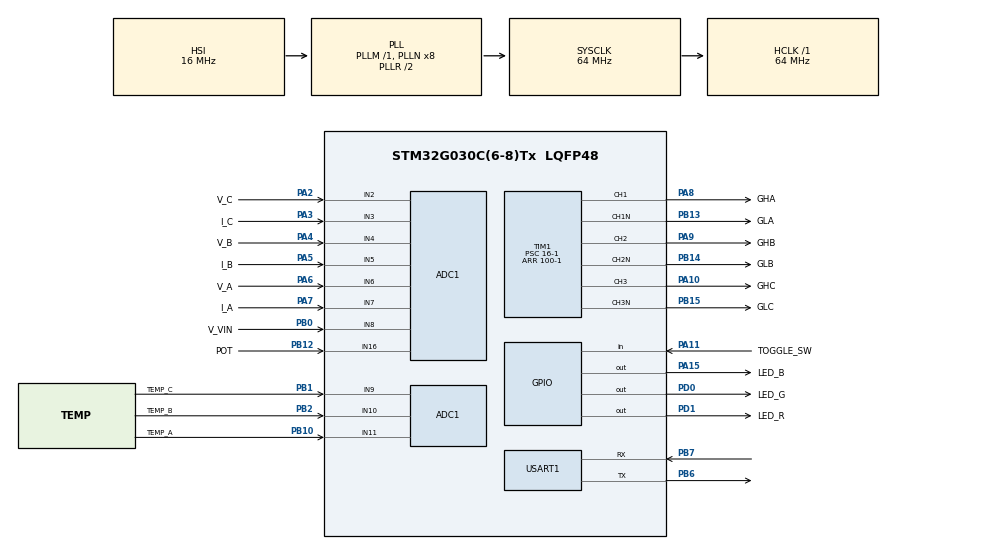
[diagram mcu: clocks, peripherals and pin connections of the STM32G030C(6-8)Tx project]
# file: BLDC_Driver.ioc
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ADC1.Channel-0\#ChannelRegularConversion=ADC_CHANNEL_2
ADC1.ContinuousConvMode=DISABLE
ADC1.DMAContinuousRequests=ENABLE
ADC1.EOCSelection=ADC_EOC_SINGLE_CONV
ADC1.ExternalTrigConv=ADC_EXTERNALTRIG_T1_TRGO2
ADC1.NbrOfConversion=1
ADC1.NbrOfConversionFlag=1
ADC1.Rank-0\#ChannelRegularConversion=1
ADC1.SamplingTime-0\#ChannelRegularConversion=__NULL
ADC1.SamplingTimeCommon1=ADC_SAMPLETIME_1CYCLE_5
ADC1.SelectedChannel=ADC_CHANNEL_2|ADC_CHANNEL_3|ADC_CHANNEL_4|ADC_CHANNEL_5|ADC_CHANNEL_6|ADC_CHANNEL_7|ADC_CHANNEL_8|ADC_CHANNEL_9|ADC_CHANNEL_10|ADC_CHANNEL_11|ADC_CHANNEL_16
ADC1.Sequencer=NOT_FULLY_CONFIGURABLE
ADC1.master=1
Dma.ADC1.0.Direction=DMA_PERIPH_TO_MEMORY
Dma.ADC1.0.EventEnable=DISABLE
Dma.ADC1.0.Instance=DMA1_Channel1
Dma.ADC1.0.MemDataAlignment=DMA_MDATAALIGN_HALFWORD
Dma.ADC1.0.MemInc=DMA_MINC_ENABLE
Dma.ADC1.0.Mode=DMA_CIRCULAR
Dma.ADC1.0.PeriphDataAlignment=DMA_PDATAALIGN_HALFWORD
Dma.ADC1.0.PeriphInc=DMA_PINC_DISABLE
Dma.ADC1.0.Polarity=HAL_DMAMUX_REQ_GEN_RISING
Dma.ADC1.0.Priority=DMA_PRIORITY_LOW
Dma.ADC1.0.RequestNumber=1
Dma.ADC1.0.SignalID=NONE
Dma.ADC1.0.SyncEnable=DISABLE
Dma.ADC1.0.SyncPolarity=HAL_DMAMUX_SYNC_NO_EVENT
Dma.ADC1.0.SyncRequestNumber=1
Dma.ADC1.0.SyncSignalID=NONE
Dma.Request0=ADC1
Dma.Request1=USART1_TX
Dma.USART1_TX.1.Direction=DMA_MEMORY_TO_PERIPH
Dma.USART1_TX.1.EventEnable=DISABLE
Dma.USART1_TX.1.Instance=DMA1_Channel2
Dma.USART1_TX.1.MemDataAlignment=DMA_MDATAALIGN_BYTE
Dma.USART1_TX.1.MemInc=DMA_MINC_ENABLE
Dma.USART1_TX.1.Mode=DMA_NORMAL
Dma.USART1_TX.1.PeriphDataAlignment=DMA_PDATAALIGN_BYTE
Dma.USART1_TX.1.PeriphInc=DMA_PINC_DISABLE
Dma.USART1_TX.1.Polarity=HAL_DMAMUX_REQ_GEN_RISING
Dma.USART1_TX.1.Priority=DMA_PRIORITY_LOW
Dma.USART1_TX.1.RequestNumber=1
Dma.USART1_TX.1.SignalID=NONE
Dma.USART1_TX.1.SyncEnable=DISABLE
Dma.USART1_TX.1.SyncPolarity=HAL_DMAMUX_SYNC_NO_EVENT
Dma.USART1_TX.1.SyncRequestNumber=1
Dma.USART1_TX.1.SyncSignalID=NONE
Mcu.Family=STM32G0
Mcu.Name=STM32G030C(6-8)Tx
Mcu.Package=LQFP48
NVIC.ADC1_IRQn=true\:0\:0\:false\:false\:true\:true\:true\:true
NVIC.DMA1_Channel1_IRQn=true\:0\:0\:false\:false\:true\:false\:true\:true
NVIC.DMA1_Channel2_3_IRQn=true\:0\:0\:false\:false\:true\:false\:true\:true
NVIC.TIM14_IRQn=true\:1\:0\:true\:false\:true\:true\:true\:true
NVIC.TIM16_IRQn=true\:0\:0\:true\:false\:true\:true\:true\:true
NVIC.TIM17_IRQn=true\:0\:0\:false\:false\:true\:true\:true\:true
NVIC.TIM1_BRK_UP_TRG_COM_IRQn=true\:0\:0\:false\:false\:true\:true\:true\:true
NVIC.TIM1_CC_IRQn=true\:0\:0\:false\:false\:true\:true\:true\:true
NVIC.USART1_IRQn=true\:0\:0\:false\:false\:true\:true\:true\:true
PA10.GPIO_Label=GHC
PA10.Signal=S_TIM1_CH3
PA11\ [PA9].GPIO_Label=TOGGLE_SW
PA11\ [PA9].GPIO_PuPd=GPIO_PULLDOWN
PA11\ [PA9].Signal=GPIO_Input
PA13.Mode=Serial_Wire
PA13.Signal=SYS_SWDIO
PA14-BOOT0.Mode=Serial_Wire
PA14-BOOT0.Signal=SYS_SWCLK
PA15.GPIO_Label=LED_B
PA15.GPIO_PuPd=GPIO_PULLDOWN
PA15.Signal=GPIO_Output
PA2.GPIO_Label=V_C
PA2.Mode=IN2
PA2.Signal=ADC1_IN2
PA3.GPIO_Label=I_C
PA3.Mode=IN3
PA3.Signal=ADC1_IN3
PA4.GPIO_Label=V_B
PA4.Mode=IN4
PA4.Signal=ADC1_IN4
PA5.GPIO_Label=I_B
PA5.Mode=IN5
PA5.Signal=ADC1_IN5
PA6.GPIO_Label=V_A
PA6.Mode=IN6
PA6.Signal=ADC1_IN6
PA7.GPIO_Label=I_A
PA7.Mode=IN7
PA7.Signal=ADC1_IN7
PA8.GPIO_Label=GHA
PA8.Signal=S_TIM1_CH1
PA9.GPIO_Label=GHB
PA9.Signal=S_TIM1_CH2
PB0.GPIO_Label=V_VIN
PB0.Mode=IN8
PB0.Signal=ADC1_IN8
PB1.GPIO_Label=TEMP_C
PB1.Mode=IN9
PB1.Signal=ADC1_IN9
PB10.GPIO_Label=TEMP_A
PB10.Mode=IN11
PB10.Signal=ADC1_IN11
PB12.GPIO_Label=POT
PB12.Mode=IN16
PB12.Signal=ADC1_IN16
PB13.GPIO_Label=GLA
PB13.Mode=PWM Generation1 CH1 CH1N
PB13.Signal=TIM1_CH1N
PB14.GPIO_Label=GLB
PB14.Mode=PWM Generation2 CH2 CH2N
PB14.Signal=TIM1_CH2N
PB15.GPIO_Label=GLC
PB15.Mode=PWM Generation3 CH3 CH3N
PB15.Signal=TIM1_CH3N
PB2.GPIO_Label=TEMP_B
PB2.Mode=IN10
PB2.Signal=ADC1_IN10
PB6.Mode=Asynchronous
PB6.Signal=USART1_TX
PB7.Mode=Asynchronous
PB7.Signal=USART1_RX
PD0.GPIO_Label=LED_G
PD0.GPIO_PuPd=GPIO_PULLDOWN
PD0.Signal=GPIO_Output
PD1.GPIO_Label=LED_R
PD1.GPIO_PuPd=GPIO_PULLDOWN
PD1.Signal=GPIO_Output
PF0-OSC_IN\ (PF0).Mode=HSE-External-Oscillator
PF0-OSC_IN\ (PF0).Signal=RCC_OSC_IN
PF1-OSC_OUT\ (PF1).Mode=HSE-External-Oscillator
PF1-OSC_OUT\ (PF1).Signal=RCC_OSC_OUT
ProjectManager.HeapSize=0x200
ProjectManager.StackSize=0x400
ProjectManager.TargetToolchain=STM32CubeIDE
RCC.ADCFreq_Value=64000000
RCC.AHBFreq_Value=64000000
RCC.CortexFreq_Value=64000000
RCC.EXTERNAL_CLOCK_VALUE=12288000
RCC.HCLKFreq_Value=64000000
RCC.HSE_VALUE=25000000
RCC.HSI_VALUE=16000000
RCC.LSE_VALUE=32768
RCC.SYSCLKFreq_VALUE=64000000
RCC.SYSCLKSource=RCC_SYSCLKSOURCE_PLLCLK
RCC.VCOOutputFreq_Value=128000000
SH.S_TIM1_CH1.0=TIM1_CH1,PWM Generation1 CH1 CH1N
SH.S_TIM1_CH2.0=TIM1_CH2,PWM Generation2 CH2 CH2N
SH.S_TIM1_CH3.0=TIM1_CH3,PWM Generation3 CH3 CH3N
TIM1.Channel-PWM\ Generation1\ CH1\ CH1N=TIM_CHANNEL_1
TIM1.Channel-PWM\ Generation2\ CH2\ CH2N=TIM_CHANNEL_2
TIM1.Channel-PWM\ Generation3\ CH3\ CH3N=TIM_CHANNEL_3
TIM1.CounterMode=TIM_COUNTERMODE_CENTERALIGNED1
TIM1.OCMode_PWM-PWM\ Generation1\ CH1\ CH1N=TIM_OCMODE_PWM1
TIM1.OCMode_PWM-PWM\ Generation2\ CH2\ CH2N=TIM_OCMODE_PWM1
TIM1.OCMode_PWM-PWM\ Generation3\ CH3\ CH3N=TIM_OCMODE_PWM1
TIM1.Period=100-1
TIM1.Prescaler=16-1
TIM1.TIM_MasterOutputTrigger=TIM_TRGO_RESET
TIM1.TIM_MasterOutputTrigger2=TIM_TRGO2_UPDATE
TIM14.Period=500-1
TIM14.Prescaler=128-1
TIM16.Period=10000-1
TIM16.Prescaler=640-1
TIM17.Period=10-1
TIM17.Prescaler=64-1
USART1.VirtualMode-Asynchronous=VM_ASYNC
VP_TIM14_VS_ClockSourceINT.Mode=Enable_Timer
VP_TIM16_VS_ClockSourceINT.Mode=Enable_Timer
VP_TIM17_VS_ClockSourceINT.Mode=Enable_Timer
VP_TIM1_VS_ClockSourceINT.Mode=Internal
board=custom

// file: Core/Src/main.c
/* USER CODE BEGIN Header */
/**
  ******************************************************************************
  * @file           : main.c
  * @brief          : Main program body
  ******************************************************************************
  * @attention
  *
  * Copyright (c) 2024 STMicroelectronics.
  * All rights reserved.
  *
  * This software is licensed under terms that can be found in the LICENSE file
  * in the root directory of this software component.
  * If no LICENSE file comes with this software, it is provided AS-IS.
  *
  ******************************************************************************
  */
/* USER CODE END Header */
#include "main.h"
#include "adc.h"
#include "dma.h"
#include "tim.h"
#include "usart.h"
#include "gpio.h"

/* USER CODE BEGIN Includes */
#include "app.h"
/* USER CODE END Includes */

void SystemClock_Config(void);

int main(void)
{

  /* MCU Configuration--------------------------------------------------------*/

  /* Reset of all peripherals, Initializes the Flash interface and the Systick. */
  HAL_Init();

  /* Configure the system clock */
  SystemClock_Config();

  /* Initialize all configured peripherals */
  MX_GPIO_Init();
  MX_DMA_Init();
  MX_ADC1_Init();
  MX_TIM1_Init();
  MX_TIM17_Init();
  MX_TIM14_Init();
  MX_TIM16_Init();
  MX_USART1_UART_Init();
  /* USER CODE BEGIN 2 */
  run_app();
  /* USER CODE END 2 */

  /* Infinite loop */
  while (1)
  {

  }
}

void SystemClock_Config(void)
{
  RCC_OscInitTypeDef RCC_OscInitStruct = {0};
  RCC_ClkInitTypeDef RCC_ClkInitStruct = {0};

  /** Configure the main internal regulator output voltage
  */
  HAL_PWREx_ControlVoltageScaling(PWR_REGULATOR_VOLTAGE_SCALE1);

  /** Initializes the RCC Oscillators according to the specified parameters
  * in the RCC_OscInitTypeDef structure.
  */
  RCC_OscInitStruct.OscillatorType = RCC_OSCILLATORTYPE_HSI;
  RCC_OscInitStruct.HSIState = RCC_HSI_ON;
  RCC_OscInitStruct.HSIDiv = RCC_HSI_DIV1;
  RCC_OscInitStruct.HSICalibrationValue = RCC_HSICALIBRATION_DEFAULT;
  RCC_OscInitStruct.PLL.PLLState = RCC_PLL_ON;
  RCC_OscInitStruct.PLL.PLLSource = RCC_PLLSOURCE_HSI;
  RCC_OscInitStruct.PLL.PLLM = RCC_PLLM_DIV1;
  RCC_OscInitStruct.PLL.PLLN = 8;
  RCC_OscInitStruct.PLL.PLLP = RCC_PLLP_DIV2;
  RCC_OscInitStruct.PLL.PLLR = RCC_PLLR_DIV2;
  if (HAL_RCC_OscConfig(&RCC_OscInitStruct) != HAL_OK)
  {
    Error_Handler();
  }

  /** Initializes the CPU, AHB and APB buses clocks
  */
  RCC_ClkInitStruct.ClockType = RCC_CLOCKTYPE_HCLK|RCC_CLOCKTYPE_SYSCLK
                              |RCC_CLOCKTYPE_PCLK1;
  RCC_ClkInitStruct.SYSCLKSource = RCC_SYSCLKSOURCE_PLLCLK;
  RCC_ClkInitStruct.AHBCLKDivider = RCC_SYSCLK_DIV1;
  RCC_ClkInitStruct.APB1CLKDivider = RCC_HCLK_DIV1;

  if (HAL_RCC_ClockConfig(&RCC_ClkInitStruct, FLASH_LATENCY_2) != HAL_OK)
  {
    Error_Handler();
  }
}

void Error_Handler(void)
{
  __disable_irq();
  while (1)
  {
  }
}
